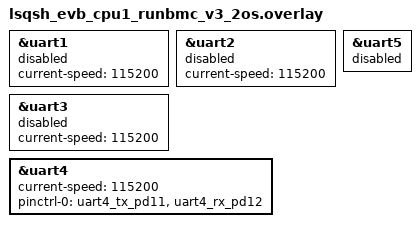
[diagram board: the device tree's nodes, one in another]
/*
 * Copyright (c) 2024, linkedsemi
 * SPDX-License-Identifier: Apache-2.0
 */

#include "lsqsh_evb_pinctrl_runbmc_v3.dtsi"

&uart1 {
    current-speed = <115200>;
    status = "disabled";
};

&uart2 {
    current-speed = <115200>;
    status = "disabled";
};

&uart3 {
    current-speed = <115200>;
    status = "disabled";
};

&uart4 {
    status = "okay";
    current-speed = <115200>;
    pinctrl-0 = <&uart4_tx_pd11 &uart4_rx_pd12>;
    pinctrl-names = "default";
};

&uart5 {
    status = "disabled";
};
